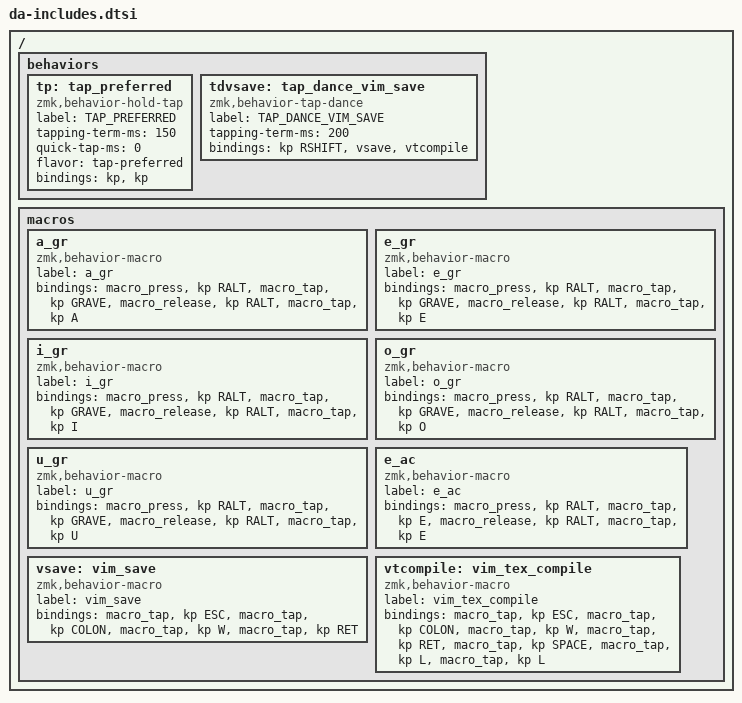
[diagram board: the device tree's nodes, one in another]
#define HYPER LC(LS(LA(LGUI)))
  
/ {

    behaviors {

      tp: tap_preferred {
        compatible = "zmk,behavior-hold-tap";
        label = "TAP_PREFERRED";
        #binding-cells = <2>;
        tapping-term-ms = <150>;
        quick-tap-ms = <0>;
        flavor = "tap-preferred";
        bindings = <&kp>, <&kp>;
      }; 
      
      tdvsave: tap_dance_vim_save {
           compatible = "zmk,behavior-tap-dance";
           label = "TAP_DANCE_VIM_SAVE";
           #binding-cells = <0>;
           tapping-term-ms = <200>;
           bindings = <&kp RSHIFT>, <&vsave>, <&vtcompile>;
      };

    };

    macros {
        
      a_gr: a_gr {
          label = "a_gr";
          compatible = "zmk,behavior-macro";
          #binding-cells = <0>;
          bindings
              = <&macro_press &kp RALT>
              , <&macro_tap &kp GRAVE >
              , <&macro_release &kp RALT>
              , <&macro_tap &kp A >
              ;
      };
        
      e_gr: e_gr {
          label = "e_gr";
          compatible = "zmk,behavior-macro";
          #binding-cells = <0>;
          bindings
              = <&macro_press &kp RALT>
              , <&macro_tap &kp GRAVE >
              , <&macro_release &kp RALT>
              , <&macro_tap &kp E >
              ;
      };
        
      i_gr: i_gr {
          label = "i_gr";
          compatible = "zmk,behavior-macro";
          #binding-cells = <0>;
          bindings
              = <&macro_press &kp RALT>
              , <&macro_tap &kp GRAVE >
              , <&macro_release &kp RALT>
              , <&macro_tap &kp I >
              ;
      };
        
      o_gr: o_gr {
          label = "o_gr";
          compatible = "zmk,behavior-macro";
          #binding-cells = <0>;
          bindings
              = <&macro_press &kp RALT>
              , <&macro_tap &kp GRAVE >
              , <&macro_release &kp RALT>
              , <&macro_tap &kp O >
              ;
      };
        
      u_gr: u_gr {
          label = "u_gr";
          compatible = "zmk,behavior-macro";
          #binding-cells = <0>;
          bindings
              = <&macro_press &kp RALT>
              , <&macro_tap &kp GRAVE >
              , <&macro_release &kp RALT>
              , <&macro_tap &kp U >
              ;
      };

      e_ac: e_ac {
          label = "e_ac";
          compatible = "zmk,behavior-macro";
          #binding-cells = <0>;
          bindings
              = <&macro_press &kp RALT>
              , <&macro_tap &kp E >
              , <&macro_release &kp RALT>
              , <&macro_tap &kp E >
              ;
      };
        
      vsave: vim_save {
          label = "vim_save";
          compatible = "zmk,behavior-macro";
          #binding-cells = <0>;
          bindings
              = <&macro_tap &kp ESC>
              , <&macro_tap &kp COLON>
              , <&macro_tap &kp W >
              , <&macro_tap &kp RET >
              ;
      };

      vtcompile: vim_tex_compile {
          label = "vim_tex_compile";
          compatible = "zmk,behavior-macro";
          #binding-cells = <0>;
          bindings
              = <&macro_tap &kp ESC>
              , <&macro_tap &kp COLON>
              , <&macro_tap &kp W>
              , <&macro_tap &kp RET>
              , <&macro_tap &kp SPACE>
              , <&macro_tap &kp L>
              , <&macro_tap &kp L>
              ;
      };
        
  };

};
